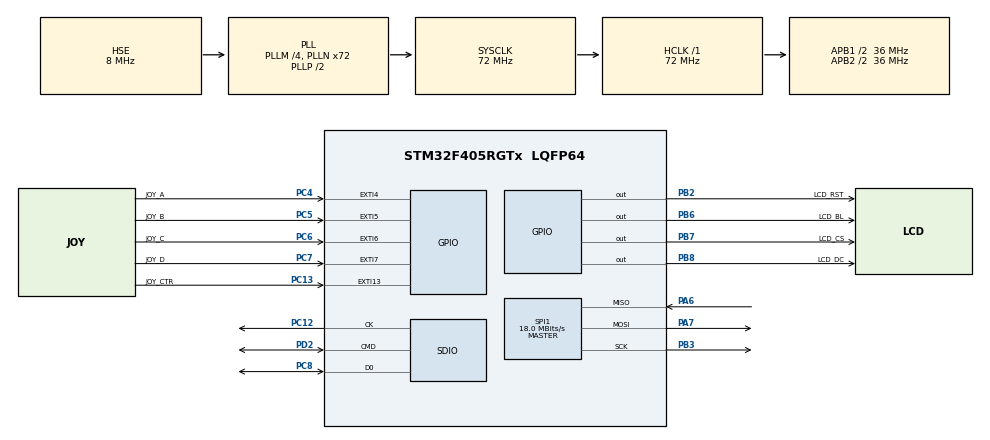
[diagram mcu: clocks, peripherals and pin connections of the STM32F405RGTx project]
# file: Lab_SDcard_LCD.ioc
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Mcu.Family=STM32F4
Mcu.Name=STM32F405RGTx
Mcu.Package=LQFP64
NVIC.EXTI15_10_IRQn=true\:1\:0\:true\:false\:true\:true\:true\:true
NVIC.EXTI4_IRQn=true\:1\:0\:true\:false\:true\:true\:true\:true
NVIC.EXTI9_5_IRQn=true\:1\:0\:true\:false\:true\:true\:true\:true
NVIC.PriorityGroup=NVIC_PRIORITYGROUP_4
NVIC.SDIO_IRQn=true\:0\:0\:false\:false\:true\:true\:true\:true
NVIC.SPI1_IRQn=true\:0\:0\:false\:false\:true\:true\:true\:true
PA13.Mode=Serial_Wire
PA13.Signal=SYS_JTMS-SWDIO
PA14.Mode=Serial_Wire
PA14.Signal=SYS_JTCK-SWCLK
PA6.Mode=Full_Duplex_Master
PA6.Signal=SPI1_MISO
PA7.Mode=Full_Duplex_Master
PA7.Signal=SPI1_MOSI
PB2.GPIO_Label=LCD_RST
PB2.Signal=GPIO_Output
PB3.Mode=Full_Duplex_Master
PB3.Signal=SPI1_SCK
PB6.GPIO_Label=LCD_BL
PB6.Signal=GPIO_Output
PB7.GPIO_Label=LCD_CS
PB7.Signal=GPIO_Output
PB8.GPIO_Label=LCD_DC
PB8.Signal=GPIO_Output
PC12.Mode=SD_1_bit
PC12.Signal=SDIO_CK
PC13-ANTI_TAMP.GPIO_Label=JOY_CTR
PC13-ANTI_TAMP.GPIO_ModeDefaultEXTI=GPIO_MODE_IT_FALLING
PC13-ANTI_TAMP.GPIO_PuPd=GPIO_PULLUP
PC13-ANTI_TAMP.Signal=GPXTI13
PC4.GPIO_Label=JOY_A
PC4.GPIO_ModeDefaultEXTI=GPIO_MODE_IT_FALLING
PC4.GPIO_PuPd=GPIO_PULLUP
PC4.Signal=GPXTI4
PC5.GPIO_Label=JOY_B
PC5.GPIO_ModeDefaultEXTI=GPIO_MODE_IT_FALLING
PC5.GPIO_PuPd=GPIO_PULLUP
PC5.Signal=GPXTI5
PC6.GPIO_Label=JOY_C
PC6.GPIO_ModeDefaultEXTI=GPIO_MODE_IT_FALLING
PC6.GPIO_PuPd=GPIO_PULLUP
PC6.Signal=GPXTI6
PC7.GPIO_Label=JOY_D
PC7.GPIO_ModeDefaultEXTI=GPIO_MODE_IT_FALLING
PC7.GPIO_PuPd=GPIO_PULLUP
PC7.Signal=GPXTI7
PC8.Mode=SD_1_bit
PC8.Signal=SDIO_D0
PD2.Mode=SD_1_bit
PD2.Signal=SDIO_CMD
PH0-OSC_IN.Mode=HSE-External-Oscillator
PH0-OSC_IN.Signal=RCC_OSC_IN
PH1-OSC_OUT.Mode=HSE-External-Oscillator
PH1-OSC_OUT.Signal=RCC_OSC_OUT
ProjectManager.HeapSize=0x200
ProjectManager.StackSize=0x400
ProjectManager.TargetToolchain=STM32CubeIDE
RCC.48MHZClocksFreq_Value=48000000
RCC.AHBFreq_Value=72000000
RCC.APB1CLKDivider=RCC_HCLK_DIV2
RCC.APB1Freq_Value=36000000
RCC.APB1TimFreq_Value=72000000
RCC.APB2CLKDivider=RCC_HCLK_DIV2
RCC.APB2Freq_Value=36000000
RCC.APB2TimFreq_Value=72000000
RCC.CortexFreq_Value=72000000
RCC.HCLKFreq_Value=72000000
RCC.HSE_VALUE=8000000
RCC.HSI_VALUE=16000000
RCC.LSE_VALUE=32768
RCC.PLLM=4
RCC.PLLN=72
RCC.PLLQ=3
RCC.PLLSourceVirtual=RCC_PLLSOURCE_HSE
RCC.SYSCLKFreq_VALUE=72000000
RCC.SYSCLKSource=RCC_SYSCLKSOURCE_PLLCLK
RCC.VCOOutputFreq_Value=144000000
SDIO.ClockDiv=10
SPI1.BaudRatePrescaler=SPI_BAUDRATEPRESCALER_2
SPI1.CLKPolarity=SPI_POLARITY_HIGH
SPI1.CalculateBaudRate=18.0 MBits/s
SPI1.Direction=SPI_DIRECTION_2LINES
SPI1.Mode=SPI_MODE_MASTER
SPI1.VirtualType=VM_MASTER
VP_FATFS_VS_SDIO.Mode=SDIO
board=custom

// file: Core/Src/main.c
/* USER CODE BEGIN Header */
/**
  ******************************************************************************
  * @file           : main.c
  * @brief          : Main program body
  ******************************************************************************
  * @attention
  *
  * Copyright (c) 2023 STMicroelectronics.
  * All rights reserved.
  *
  * This software is licensed under terms that can be found in the LICENSE file
  * in the root directory of this software component.
  * If no LICENSE file comes with this software, it is provided AS-IS.
  *
  ******************************************************************************
  */
/* USER CODE END Header */
#include "main.h"
#include "fatfs.h"

/* USER CODE BEGIN Includes */
#include "system.h"
/* USER CODE END Includes */

SD_HandleTypeDef hsd;

SPI_HandleTypeDef hspi1;

void SystemClock_Config(void);
static void MX_GPIO_Init(void);
static void MX_SPI1_Init(void);
static void MX_SDIO_SD_Init(void);

int main(void)
{

  /* MCU Configuration--------------------------------------------------------*/

  /* Reset of all peripherals, Initializes the Flash interface and the Systick. */
  HAL_Init();

  /* Configure the system clock */
  SystemClock_Config();

  /* Initialize all configured peripherals */
  MX_GPIO_Init();
  MX_SPI1_Init();
  MX_SDIO_SD_Init();
  MX_FATFS_Init();
  /* USER CODE BEGIN 2 */
  system_init();
  /* USER CODE END 2 */

  /* Infinite loop */
  while (1)
  {
	  system_process();
  }
}

void SystemClock_Config(void)
{
  RCC_OscInitTypeDef RCC_OscInitStruct = {0};
  RCC_ClkInitTypeDef RCC_ClkInitStruct = {0};

  /** Configure the main internal regulator output voltage
  */
  __HAL_RCC_PWR_CLK_ENABLE();
  __HAL_PWR_VOLTAGESCALING_CONFIG(PWR_REGULATOR_VOLTAGE_SCALE1);

  /** Initializes the RCC Oscillators according to the specified parameters
  * in the RCC_OscInitTypeDef structure.
  */
  RCC_OscInitStruct.OscillatorType = RCC_OSCILLATORTYPE_HSE;
  RCC_OscInitStruct.HSEState = RCC_HSE_ON;
  RCC_OscInitStruct.PLL.PLLState = RCC_PLL_ON;
  RCC_OscInitStruct.PLL.PLLSource = RCC_PLLSOURCE_HSE;
  RCC_OscInitStruct.PLL.PLLM = 4;
  RCC_OscInitStruct.PLL.PLLN = 72;
  RCC_OscInitStruct.PLL.PLLP = RCC_PLLP_DIV2;
  RCC_OscInitStruct.PLL.PLLQ = 3;
  if (HAL_RCC_OscConfig(&RCC_OscInitStruct) != HAL_OK)
  {
    Error_Handler();
  }

  /** Initializes the CPU, AHB and APB buses clocks
  */
  RCC_ClkInitStruct.ClockType = RCC_CLOCKTYPE_HCLK|RCC_CLOCKTYPE_SYSCLK
                              |RCC_CLOCKTYPE_PCLK1|RCC_CLOCKTYPE_PCLK2;
  RCC_ClkInitStruct.SYSCLKSource = RCC_SYSCLKSOURCE_PLLCLK;
  RCC_ClkInitStruct.AHBCLKDivider = RCC_SYSCLK_DIV1;
  RCC_ClkInitStruct.APB1CLKDivider = RCC_HCLK_DIV2;
  RCC_ClkInitStruct.APB2CLKDivider = RCC_HCLK_DIV2;

  if (HAL_RCC_ClockConfig(&RCC_ClkInitStruct, FLASH_LATENCY_2) != HAL_OK)
  {
    Error_Handler();
  }
}

static void MX_SDIO_SD_Init(void)
{

  hsd.Instance = SDIO;
  hsd.Init.ClockEdge = SDIO_CLOCK_EDGE_RISING;
  hsd.Init.ClockBypass = SDIO_CLOCK_BYPASS_DISABLE;
  hsd.Init.ClockPowerSave = SDIO_CLOCK_POWER_SAVE_DISABLE;
  hsd.Init.BusWide = SDIO_BUS_WIDE_1B;
  hsd.Init.HardwareFlowControl = SDIO_HARDWARE_FLOW_CONTROL_DISABLE;
  hsd.Init.ClockDiv = 10;

}

static void MX_SPI1_Init(void)
{

  /* SPI1 parameter configuration*/
  hspi1.Instance = SPI1;
  hspi1.Init.Mode = SPI_MODE_MASTER;
  hspi1.Init.Direction = SPI_DIRECTION_2LINES;
  hspi1.Init.DataSize = SPI_DATASIZE_8BIT;
  hspi1.Init.CLKPolarity = SPI_POLARITY_HIGH;
  hspi1.Init.CLKPhase = SPI_PHASE_1EDGE;
  hspi1.Init.NSS = SPI_NSS_SOFT;
  hspi1.Init.BaudRatePrescaler = SPI_BAUDRATEPRESCALER_2;
  hspi1.Init.FirstBit = SPI_FIRSTBIT_MSB;
  hspi1.Init.TIMode = SPI_TIMODE_DISABLE;
  hspi1.Init.CRCCalculation = SPI_CRCCALCULATION_DISABLE;
  hspi1.Init.CRCPolynomial = 10;
  if (HAL_SPI_Init(&hspi1) != HAL_OK)
  {
    Error_Handler();
  }

}

static void MX_GPIO_Init(void)
{
  GPIO_InitTypeDef GPIO_InitStruct = {0};

  /* GPIO Ports Clock Enable */
  __HAL_RCC_GPIOC_CLK_ENABLE();
  __HAL_RCC_GPIOH_CLK_ENABLE();
  __HAL_RCC_GPIOA_CLK_ENABLE();
  __HAL_RCC_GPIOB_CLK_ENABLE();
  __HAL_RCC_GPIOD_CLK_ENABLE();

  /*Configure GPIO pin Output Level */
  HAL_GPIO_WritePin(GPIOB, LCD_RST_Pin|LCD_BL_Pin|LCD_CS_Pin|LCD_DC_Pin, GPIO_PIN_RESET);

  /*Configure GPIO pins : JOY_CTR_Pin JOY_A_Pin JOY_B_Pin JOY_C_Pin
                           JOY_D_Pin */
  GPIO_InitStruct.Pin = JOY_CTR_Pin|JOY_A_Pin|JOY_B_Pin|JOY_C_Pin
                          |JOY_D_Pin;
  GPIO_InitStruct.Mode = GPIO_MODE_IT_FALLING;
  GPIO_InitStruct.Pull = GPIO_PULLUP;
  HAL_GPIO_Init(GPIOC, &GPIO_InitStruct);

  /*Configure GPIO pins : LCD_RST_Pin LCD_BL_Pin LCD_CS_Pin LCD_DC_Pin */
  GPIO_InitStruct.Pin = LCD_RST_Pin|LCD_BL_Pin|LCD_CS_Pin|LCD_DC_Pin;
  GPIO_InitStruct.Mode = GPIO_MODE_OUTPUT_PP;
  GPIO_InitStruct.Pull = GPIO_NOPULL;
  GPIO_InitStruct.Speed = GPIO_SPEED_FREQ_LOW;
  HAL_GPIO_Init(GPIOB, &GPIO_InitStruct);

  /* EXTI interrupt init*/
  HAL_NVIC_SetPriority(EXTI4_IRQn, 1, 0);
  HAL_NVIC_EnableIRQ(EXTI4_IRQn);

  HAL_NVIC_SetPriority(EXTI9_5_IRQn, 1, 0);
  HAL_NVIC_EnableIRQ(EXTI9_5_IRQn);

  HAL_NVIC_SetPriority(EXTI15_10_IRQn, 1, 0);
  HAL_NVIC_EnableIRQ(EXTI15_10_IRQn);

}

void Error_Handler(void)
{
  __disable_irq();
  while (1)
  {
  }
}
